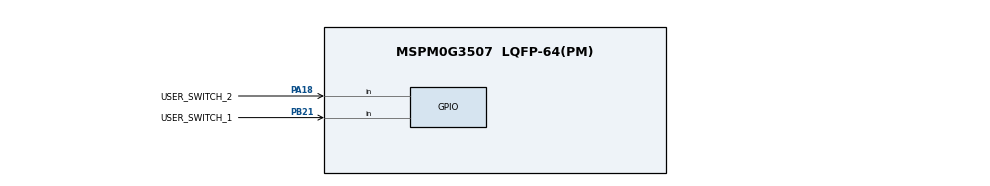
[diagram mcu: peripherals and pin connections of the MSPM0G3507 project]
//@cliArgs --device "MSPM0G350X" --package "LQFP-64(PM)" --part "Default"
//@v2CliArgs --device "MSPM0G3507" --package "LQFP-64(PM)"
// @cliArgs --board /ti/boards/LP_MSPM0G3507 --rtos nortos

/**
 * Import the modules used in this configuration.
 */
const GPIO   = scripting.addModule("/ti/driverlib/GPIO", {}, false);
const GPIO1  = GPIO.addInstance();
const GPIO2  = GPIO.addInstance();
const GPIO3  = GPIO.addInstance();
const SYSCTL = scripting.addModule("/ti/driverlib/SYSCTL");

/**
 * Write custom configuration values to the imported modules.
 */
GPIO1.$name                         = "GPIO_LEDS";
GPIO1.port                          = "PORTB";
GPIO1.associatedPins.create(2);
GPIO1.associatedPins[0].$name       = "USER_LED_1";
GPIO1.associatedPins[0].assignedPin = "22";
GPIO1.associatedPins[1].$name       = "USER_LED_2";
GPIO1.associatedPins[1].assignedPin = "26";

GPIO2.$name                               = "GPIO_SWITCHES1";
GPIO2.associatedPins[0].$name             = "USER_SWITCH_1";
GPIO2.associatedPins[0].polarity          = "FALL";
GPIO2.associatedPins[0].interruptEn       = true;
GPIO2.associatedPins[0].internalResistor = "PULL_UP";
GPIO2.associatedPins[0].direction        = "INPUT";
GPIO2.associatedPins[0].pin.$assign      = "PB21";

GPIO3.$name                              = "GPIO_SWITCHES2";
GPIO3.associatedPins[0].$name            = "USER_SWITCH_2";
GPIO3.associatedPins[0].interruptEn      = true;
GPIO3.associatedPins[0].polarity         = "FALL";
GPIO3.associatedPins[0].direction        = "INPUT";
GPIO3.associatedPins[0].internalResistor = "NONE";
GPIO3.associatedPins[0].pin.$assign      = "PA18";

const Board = scripting.addModule("/ti/driverlib/Board", {}, false);

SYSCTL.forceDefaultClkConfig = true;
